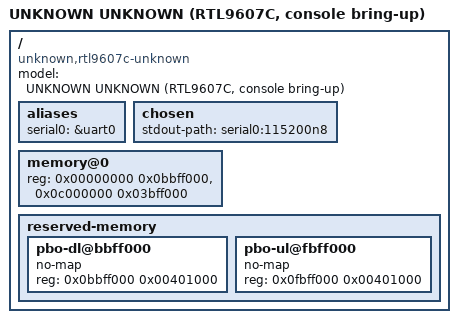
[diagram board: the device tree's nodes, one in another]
// SPDX-License-Identifier: GPL-2.0-or-later
/dts-v1/;

#include "rtl9607c.dtsi"

/ {
	model = "UNKNOWN UNKNOWN (RTL9607C, console bring-up)";
	compatible = "unknown,rtl9607c-unknown", "realtek,rtl9607c", "rtk,8198d";

	aliases {
		serial0 = &uart0;
	};

	chosen {
		stdout-path = "serial0:115200n8";
	};

	/* This unit's low RAM map, bounded by bdinfo's 256 MiB; fitted RAM is unknown. */
	memory@0 {
		reg = <0x00000000 0x0bbff000>, <0x0c000000 0x03bff000>;
	};

	reserved-memory {
		/delete-node/ ipc-shm@10000000;

		pbo-dl@bbff000 {
			no-map;
			reg = <0x0bbff000 0x00401000>;
		};

		pbo-ul@fbff000 {
			no-map;
			reg = <0x0fbff000 0x00401000>;
		};
	};

	/delete-node/ board_setting;
	/* ethernet@18012000 KEPT (2026-09-29): luna_eth binds it and needs none of
	 * the nodes deleted here; the LAN address comes from 09-luna-lan-addr (.14). */
	/delete-node/ switch@0;
	/delete-node/ gpio@1b000038;
	/delete-node/ soft_ipc@18141180;
	/delete-node/ usb@0;
	/delete-node/ usb@1;
	/delete-node/ usb@2;
};
